# tviic2d6mddr register map
Vendor: Cypress Semiconductor; Series: tviic2d6mddr; File version: 1.0
CPU: CM7 r0p1, little endian, MPU, FPU, VTOR, 3 interrupt priority bits
Registers are 32-bit, read-write, reset 0x0 unless marked. A register's access mark holds for its fields unless they carry their own. Offsets are from the block's base; [hi:lo] are bit positions; lines under a group give offsets from that group.

## VIDEOSS0 (part 16 of 18) — Video and Graphics Subsystem IP
Base 0x40A00000
0xD0000 MIPICSI group
  0x00 MIPICSI_STRUCT group — MIPICSI Structure
    0x00 MIPICSI_WRAP group — MIPI CSI-2 D-PHY wrapper configuration and status
      0x00 CTL — Control
        [31] ENABLED — Receiver enable: '0': Disabled. If a receiver is disabled, the state of the CSI-2 receiver core is initialized. Note, that MMIO registers in the core and the wrapper are accessible. Configuration of the wrapper registers should be changed only while ENABLED=0. In this state all status registers of the wrapper cannot be read. Any attempt to do so will return an error response. '1': Enabled. The CSI-2 receiver core starts its operation. Note, that CTL registers other than this ENABLED bit should not be changed in this state. It can take up to 10 cycles of selected ESC clock until wrapper status registers can be read after changing ENABLED to '1'. Note: For using MIPI a running VIDEOSS clock is required. Ensure also that VIDEOSS0_VIDEOSSCFG_IPCTRL:CTLENABLED=0x1.
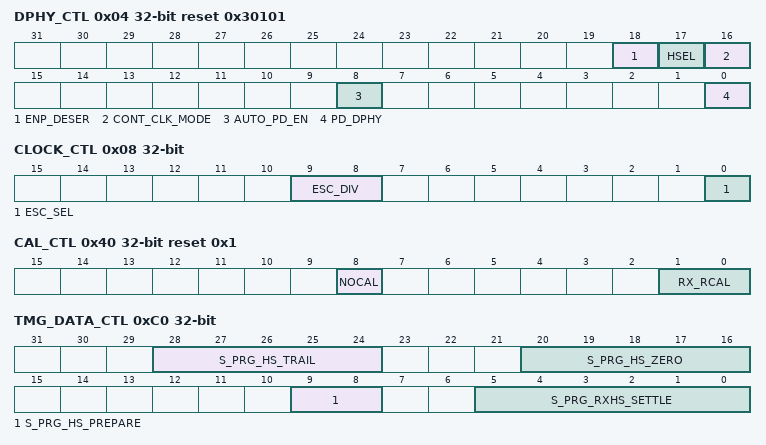
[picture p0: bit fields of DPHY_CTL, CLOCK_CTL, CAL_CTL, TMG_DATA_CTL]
      0x04 DPHY_CTL reset 0x30101 — D-PHY Control
        [18] ENP_DESER — To override the deserializer token detector and enable token detection in CIL. 1'b1: Sync token detection in the CIL. 1'b0: Sync token detection in the hard macro. For characterization and debug, we can disable this feature and enable it in the CIL (can be set to '1' for INT_LB, HSRX_SEQ and HSRX tests). With ENP_DESER=1 every lane operates independent, with ENP_DESER=0 all lanes at RX side will depend on lane 0 (default for CSI application).
        [17] HSEL — High Speed Select. 1'b0: up to 1.0 Gbps operation 1'b1: above 1.0 Gbps operation
        [16] CONT_CLK_MODE — Enables the slave clock lane feature to maintain HS reception state during continuous clock mode operation. 1'b1: Feature enabled 1'b0: Feature disabled Detail: This bit enables an advanced feature in continues clock mode operation. If the CSI link was configured to continuous clock mode, the master clock lane sends HS entry command only once and remains in HS mode. In such case, if the slave clock lane got accidentally out of HS (For example: ESD on CKP/CKN lines caused LP11 level) the master side will not sense such a disruption and will continue sending packets. Having slave clock lane out of HS mode, all packets will be not be received. Setting CONT_CLK_MODE pin to 1'b1, will help getting the slave clock lane back into HS mode, without receiving a new HS entry command from the master clock lane. It will basically rely on the fact that slave data lanes will receive HS entry command per every burst. If you think that such a feature is not required, you can set this bit to 1'b0.
        [8] AUTO_PD_EN — Powers down inactive lanes reported by CFG_NUM_LANES input bus. 1'b0: inactive lanes are powered up and driving LP11. 1'b1: inactive lanes are powered down (Hi-Z).
        [0] PD_DPHY — D-PHY power down: '1': PHY is in power down. '0': PHY is in operation.
      0x08 CLOCK_CTL — Clock Control
        [9:8] ESC_DIV — Escape Clock Divider. '00': divide by 1 '01': divide by 2 '10': divide by 3 '11': divide by 4 Note: If ESC_DIV_PRESENT=0, that bits do not have an effect.
        [0] ESC_SEL — Escape Clock Select. '0': clk_video '1': clk_sys (clk_slow in videoss)
      0x40 CAL_CTL reset 0x1 — Calibration Control
        [8] NOCAL — To override calibration value set by auto-calibration circuit with RX_RCAL[1:0]. 1'b0: Auto-calibration operation. 1'b1: Bypass the calibrator. Externally control the HS-RX termination resistance with RX_RCAL[1:0]
        [1:0] RX_RCAL — On-chip termination control bits for manual calibration. This setting has only an effect when NOCAL=1. 2'b00: 20 percent higher than mid-range. Highest impedance setting 2'b01: Mid-range impedance setting. 2'b10: 15 percent lower than mid-range 2'b11: 25 percent lower than mid-range. Lowest setting.
      0x44 CAL_STAT ro — Calibration Status
        [1:0] CALOUT — Calibrator Outputs which internally control the HS-RX resistor calibration. Exposed as outputs for monitoring purposes. 2'b00: Expected Calibrator output for fast resistor process. 2'b01: Expected Calibrator output for typical resistor process. 2'b10: Expected Calibrator output for slow resistor process. 2'b11: Expected Calibrator output for slow resistor process. When read in case CTL.ENABLED = 0, a bus error is returned. It can take up to 10 cycles of selected ESC clock until this register can be read after changing CTL.ENABLED to '1'.
      0xC0 TMG_DATA_CTL — Timing Data Lane Control
        [28:24] S_PRG_HS_TRAIL
        [20:16] S_PRG_HS_ZERO
        [9:8] S_PRG_HS_PREPARE
        [5:0] S_PRG_RXHS_SETTLE — Settling time to neglect transition effects for data. Ideally in the middle of the min/max range for THS-SETTLE. Depends on the bit rate (UI, unit interval time) and ESC clock period (T_ESC). PRG_RXHS_SETTLE = round (((115 ns + 8*UI) / T_ESC) - 2.5). Examples for 60 MHz ESC clock: 5: 500 Mbps and above 6: 250 Mbps 10: 80 Mbps
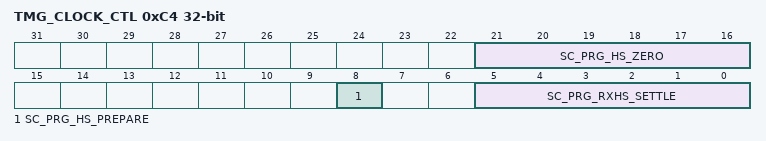
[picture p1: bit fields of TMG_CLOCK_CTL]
      0xC4 TMG_CLOCK_CTL — Timing Clock Lane Control
        [21:16] SC_PRG_HS_ZERO
        [8] SC_PRG_HS_PREPARE
        [5:0] SC_PRG_RXHS_SETTLE — Settling time to neglect transition effects for clock. See TMG_DATA_CTL.
    0x200 MIPICSI_CORE group — MIPICSI2 RX Core through APB interface (3PIP)
      0x00 CFG_NUM_LANES — CFG_NUM_LANES is a register within the CSI-2 RX Controller Core.
        [3:0] CFG_NUM_LANES
      0x04 CFG_CLK_LANE_EN — CFG_CLK_LANE_EN is a register within the CSI-2 RX Controller Core.
        [0] CFG_CLK_LANE_EN — Setting this bit enables the PHY clock lane.
      0x08 CFG_DATA_LANE_EN — CFG_DATA_LANE_EN is a register within the CSI-2 RX Controller Core.
        [3:0] CFG_DATA_LANE_EN — Setting bits to a '1' value enabled the according data lanes of the PHY.
      0x0C CFG_FLUSH_COUNT reset 0x3 — CFG_FLUSH_COUNT is a register within the CSI-2 RX Controller Core.
        [3:0] CFG_FLUSH_COUNT — Sets the number of cycles to wait at the end of flushing out the receive data FIFOs to guarantee that the FIFOs are empty. Data from the PHY is written into the RX controller receive FIFOs at the MIPI receive rate and is read out of the receive FIFOs at the main RX controller clock rate (clk_video). Since the core clock can be much faster than the MIPI receive rate, there is a settling time for FIFO pointers to cross clock boundaries and show that the FIFO is empty. Without this settling time, the very last write could still be in the FIFO, but the RX controller assumes it has not received all the expected data because it sees the FIFO empty and signals an exit_hs_error type error. Default recommend value is 4'd3 for this input to have the RX Controller wait 4 cycles before accepting that the FIFO is empty. If the ratio between MIPI rate and core clock is 20:1 or greater, it is recommended to set this value to 4'd7 to give additional time. Larger values may be used, but if set too high, it is possible for the controller to not have enough time to finish the current packet and be ready to receive the next packet. Example: At the lowest MIPI rate of 80Mbps, the write clock frequency will be 10Mhz (80 bits / 8 bits per byte). If RX Controller main clock (clk_video) is running at 250Mhz, the ratio is 250/10 or 25:1, so CFG_FLUSH_COUNT should be set for 4'd7.
      0x10 CFG_BIT_ERR ro — CFG_BIT_ERR is a register within the CSI-2 RX Controller Core.
        [9:0] BIT_ERR
      0x14 IRQ_STATUS ro — IRQ_STATUS is a register within the CSI-2 RX Controller Core.
        [7:0] IRQ_STATUS
      0x18 IRQ_ENABLE — IRQ_ENABLE is a register within the CSI-2 RX Controller Core.
        [7:0] IRQ_ENABLE — IRQ mask setting. Each bit in IRQ_ENABLE corresponds to each bit in IRQ_STATUS. Setting a bit in IRQ_ENABLE to 1 will prevent the corresponding bit in IRQ_STATUS from causing MIPI Rx Controller interrupt output to assert. Note: Bits 5 and 6 do not have any meaning.
      0x1C IRQ_CLR — IRQ_CLR is a register within the CSI-2 RX Controller Core.
        [7:0] IRQ_CLR — IRQ status clear. Writing a '1' value to each bit clears the corresponding bit in IRQ_STATUS. A '0' value must be written after the '1'. No time requirement between the '1' and '0' write operations.
      0x20 ULPS_CLK_STATUS ro — ULPS_CLK_STATUS is a register within the CSI-2 RX Controller Core.
        [0] ULPS_CLK_STATUS — Status of RX Clock Lane. [0] - Clock Lane in ULPS state when 1
      0x24 ULPS_STATUS ro — ULPS_STATUS is a register within the CSI-2 RX Controller Core.
        [3:0] ULPS_STATUS — Status of RX D-PHY ULPS state. [0] - Data Lane 0 in ULPS state when 1 [1] - Data Lane 1 in ULPS state when 1 [2] - Data Lane 2 in ULPS state when 1 [3] - Data Lane 3 in ULPS state when 1
      0x28 ULPS_CLK_MARK_STATUS ro — ULPS_CLK_MARK_STATUS is a register within the CSI-2 RX Controller Core.
        [0] ULPS_CLK_MARK_STATUS — Mark status of RX ULPS state. [0] - Clock Lane in Mark state when 1
      0x2C ULPS_MARK_STATUS ro — ULPS_MARK_STATUS is a register within the CSI-2 RX Controller Core.
        [3:0] ULPS_MARK_STATUS — Mark status of RX D-PHY ULPS state. [0] - Data Lane 0 in Mark state when 1 [1] - Data Lane 1 in Mark state when 1 [2] - Data Lane 2 in Mark state when 1 [3] - Data Lane 3 in Mark state when 1
      0x58 CFG_DISABLE_PAYLOAD_0 — CFG_DISABLE_PAYLOAD_0 is a register within the CSI-2 RX Controller Core.
      0x5C CFG_DISABLE_PAYLOAD_1 — CFG_DISABLE_PAYLOAD_1 is a register within the CSI-2 RX Controller Core.
        [16:0] CFG_DISABLE_PAYLOAD_1
